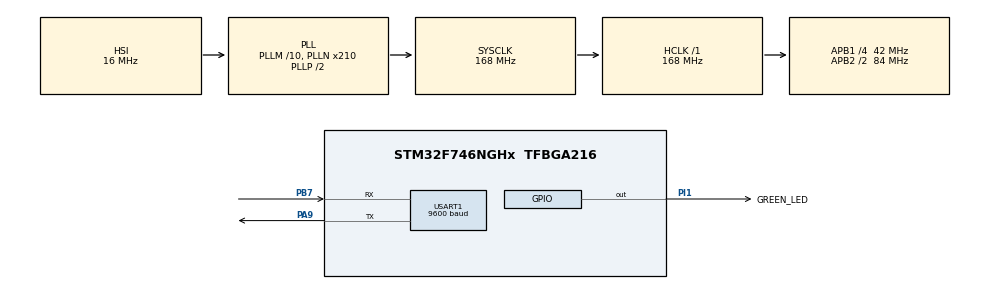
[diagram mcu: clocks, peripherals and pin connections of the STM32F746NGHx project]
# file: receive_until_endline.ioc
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Mcu.Family=STM32F7
Mcu.Name=STM32F746NGHx
Mcu.Package=TFBGA216
NVIC.PriorityGroup=NVIC_PRIORITYGROUP_4
NVIC.TIM8_TRG_COM_TIM14_IRQn=true\:0\:0\:false\:false\:true\:false\:true
NVIC.TimeBase=TIM8_TRG_COM_TIM14_IRQn
NVIC.TimeBaseIP=TIM14
NVIC.USART1_IRQn=true\:1\:0\:true\:false\:true\:true\:true
PA13.Mode=Serial_Wire
PA13.Signal=SYS_JTMS-SWDIO
PA14.Mode=Serial_Wire
PA14.Signal=SYS_JTCK-SWCLK
PA9.Mode=Asynchronous
PA9.Signal=USART1_TX
PB7.Mode=Asynchronous
PB7.Signal=USART1_RX
PC14/OSC32_IN.Mode=LSE-External-Clock-Source
PC14/OSC32_IN.Signal=RCC_OSC32_IN
PC15/OSC32_OUT.Mode=LSE-External-Clock-Source
PC15/OSC32_OUT.Signal=RCC_OSC32_OUT
PH0/OSC_IN.Mode=HSE-External-Oscillator
PH0/OSC_IN.Signal=RCC_OSC_IN
PH1/OSC_OUT.Mode=HSE-External-Oscillator
PH1/OSC_OUT.Signal=RCC_OSC_OUT
PI1.GPIO_Label=GREEN_LED
PI1.Signal=GPIO_Output
ProjectManager.HeapSize=0x200
ProjectManager.StackSize=0x400
ProjectManager.TargetToolchain=STM32CubeIDE
RCC.AHBFreq_Value=168000000
RCC.APB1CLKDivider=RCC_HCLK_DIV4
RCC.APB1Freq_Value=42000000
RCC.APB1TimFreq_Value=84000000
RCC.APB2CLKDivider=RCC_HCLK_DIV2
RCC.APB2Freq_Value=84000000
RCC.APB2TimFreq_Value=168000000
RCC.CortexFreq_Value=168000000
RCC.HCLKFreq_Value=168000000
RCC.HSE_VALUE=25000000
RCC.HSI_VALUE=16000000
RCC.LSE_VALUE=32768
RCC.PLLM=10
RCC.PLLN=210
RCC.PLLSourceVirtual=RCC_PLLSOURCE_HSI
RCC.SYSCLKFreq_VALUE=168000000
RCC.SYSCLKSource=RCC_SYSCLKSOURCE_PLLCLK
RCC.USBFreq_Value=168000000
RCC.VCOOutputFreq_Value=336000000
USART1.BaudRate=9600
USART1.VirtualMode-Asynchronous=VM_ASYNC
VP_SYS_VS_tim14.Mode=TIM14
board=STM32F746G-DISCO

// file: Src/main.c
/* USER CODE BEGIN Header */
/**
 ******************************************************************************
 * @file           : main.c
 * @brief          : Main program body
 ******************************************************************************
 * @attention
 *
 * <h2><center>&copy; Copyright (c) 2019 STMicroelectronics.
 * All rights reserved.</center></h2>
 *
 * This software component is licensed by ST under BSD 3-Clause license,
 * the "License"; You may not use this file except in compliance with the
 * License. You may obtain a copy of the License at:
 *                        opensource.org/licenses/BSD-3-Clause
 *
 ******************************************************************************
 */
/* USER CODE END Header */

#include "main.h"
#include "usart.h"
#include "gpio.h"

/* USER CODE BEGIN PV */
char buffer[255];
int counter = 0;
int lets_print = 0;

/* USER CODE END PV */

void SystemClock_Config(void);

int main(void)
{

  /* MCU Configuration--------------------------------------------------------*/

  /* Reset of all peripherals, Initializes the Flash interface and the Systick. */
  HAL_Init();

  /* Configure the system clock */
  SystemClock_Config();

  /* Initialize all configured peripherals */
  MX_GPIO_Init();
  MX_USART1_UART_Init();
  /* USER CODE BEGIN 2 */
  HAL_UART_Receive_IT(&huart1, (uint8_t*)&buffer[counter], 1);
  /* USER CODE END 2 */

  /* Infinite loop */
  /* USER CODE BEGIN WHILE */
  while (1) {

    if (lets_print) {

      buffer[counter + 1] = '\0';
      for (int i = 0; i <= counter; i++) {
        HAL_UART_Transmit(&huart1, (uint8_t*)&buffer[i], 1, 20);
      }

      counter = 0;
      lets_print = 0;
      HAL_UART_Receive_IT(&huart1, (uint8_t*)&buffer[counter], 1);
    }

    /* USER CODE END WHILE */

  }
}

void SystemClock_Config(void)
{
  RCC_OscInitTypeDef RCC_OscInitStruct = {0};
  RCC_ClkInitTypeDef RCC_ClkInitStruct = {0};
  RCC_PeriphCLKInitTypeDef PeriphClkInitStruct = {0};

  /** Configure the main internal regulator output voltage
  */
  __HAL_RCC_PWR_CLK_ENABLE();
  __HAL_PWR_VOLTAGESCALING_CONFIG(PWR_REGULATOR_VOLTAGE_SCALE2);
  /** Initializes the CPU, AHB and APB busses clocks
  */
  RCC_OscInitStruct.OscillatorType = RCC_OSCILLATORTYPE_HSI;
  RCC_OscInitStruct.HSIState = RCC_HSI_ON;
  RCC_OscInitStruct.HSICalibrationValue = RCC_HSICALIBRATION_DEFAULT;
  RCC_OscInitStruct.PLL.PLLState = RCC_PLL_ON;
  RCC_OscInitStruct.PLL.PLLSource = RCC_PLLSOURCE_HSI;
  RCC_OscInitStruct.PLL.PLLM = 10;
  RCC_OscInitStruct.PLL.PLLN = 210;
  RCC_OscInitStruct.PLL.PLLP = RCC_PLLP_DIV2;
  RCC_OscInitStruct.PLL.PLLQ = 2;
  if (HAL_RCC_OscConfig(&RCC_OscInitStruct) != HAL_OK)
  {
    Error_Handler();
  }
  /** Initializes the CPU, AHB and APB busses clocks
  */
  RCC_ClkInitStruct.ClockType = RCC_CLOCKTYPE_HCLK|RCC_CLOCKTYPE_SYSCLK
                              |RCC_CLOCKTYPE_PCLK1|RCC_CLOCKTYPE_PCLK2;
  RCC_ClkInitStruct.SYSCLKSource = RCC_SYSCLKSOURCE_PLLCLK;
  RCC_ClkInitStruct.AHBCLKDivider = RCC_SYSCLK_DIV1;
  RCC_ClkInitStruct.APB1CLKDivider = RCC_HCLK_DIV4;
  RCC_ClkInitStruct.APB2CLKDivider = RCC_HCLK_DIV2;

  if (HAL_RCC_ClockConfig(&RCC_ClkInitStruct, FLASH_LATENCY_5) != HAL_OK)
  {
    Error_Handler();
  }
  PeriphClkInitStruct.PeriphClockSelection = RCC_PERIPHCLK_USART1;
  PeriphClkInitStruct.Usart1ClockSelection = RCC_USART1CLKSOURCE_PCLK2;
  if (HAL_RCCEx_PeriphCLKConfig(&PeriphClkInitStruct) != HAL_OK)
  {
    Error_Handler();
  }
}

/* USER CODE BEGIN 4 */

void HAL_UART_RxCpltCallback(UART_HandleTypeDef *huart) {

  if (huart->Instance == USART1) {

    //HAL_GPIO_WritePin(GREEN_LED_GPIO_Port, GREEN_LED_Pin, GPIO_PIN_SET);

    if (buffer[counter] == '\n') {
      lets_print = 1;

    } else {
      counter++;

      HAL_UART_Receive_IT(&huart1, (uint8_t*) &buffer[counter], 1);
    }

  }
}
/* USER CODE END 4 */

void HAL_TIM_PeriodElapsedCallback(TIM_HandleTypeDef *htim)
{
  if (htim->Instance == TIM14) {
    HAL_IncTick();
  }
}

void Error_Handler(void)
{
}

/************************ (C) COPYRIGHT STMicroelectronics *****END OF FILE****/
